# FM33LG0XX register map
File version: 1.0
CPU: SC123 r1p0, little endian, no MPU, no FPU, 3 interrupt priority bits
Registers are 32-bit, read-write, reset 0x0 unless marked. A register's access mark holds for its fields unless they carry their own. Offsets are from the block's base; [hi:lo] are bit positions; {n}, {i} and the like mark numbered series.

## CRC — CRC module information
Base 0x40010000
0x00 DR reset 0xFFFFFFFF — CRC Data Register
  [31:0] CRCDR — CRCDR field description
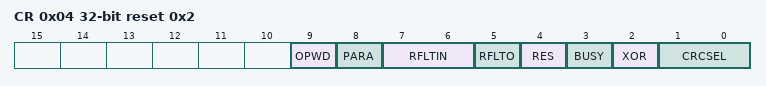
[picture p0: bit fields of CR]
0x04 CR access per field reset 0x2 — CRC Control Register
  [9] OPWD rw — OPWD field description
  [8] PARA rw — PARA field description
  [7:6] RFLTIN rw — RFLTIN field description
  [5] RFLTO rw — RFLTO field description
  [4] RES ro — RES field description
  [3] BUSY ro — BUSY field description
  [2] XOR rw — XOR field description
  [1:0] CRCSEL rw — CRCSEL field description
0x08 LFSR reset 0xFFFFFFFF — CRC Linear Feedback Shift Register
  [31:0] LFSR — LFSR field description
0x0C XOR — CRC output XOR Register
  [31:0] CRC_XOR — CRC_XOR field description
0x1C POLY reset 0x1021 — CRC Polynominal Register
  [31:0] CRCPOLY — CRCPOLY field description

## BSTIM32 — BSTIM32 module information
Base 0x40016000
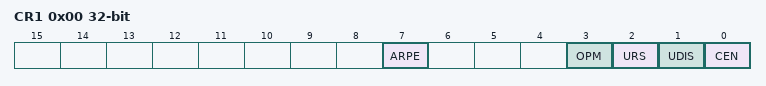
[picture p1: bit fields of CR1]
0x00 CR1 — BSTIM32 Control Register1
  [7] ARPE — ARPE field description
  [3] OPM — OPM field description
  [2] URS — URS field description
  [1] UDIS — UDIS field description
  [0] CEN — CEN field description
0x04 CR2 — BSTIM32 Control Register2
  [6:4] MMS — MMS field description
0x0C IER — BSTIM32 Interrupt Enable Register
  [0] UIE — UIE field description
0x10 ISR — BSTIM32 Interrupt Status Register
  [0] UIF — UIF field description
0x14 EGR wo — BSTIM32 Event Generation Register
  [0] UG — UG field description
0x24 CNT — BSTIM32 Counter Register
  [31:0] CNT — CNT field description
0x28 PSC — BSTIM32 Prescaler Register
  [31:0] PSC — PSC field description
0x2C ARR reset 0xFFFFFFFF — BSTIM32 Auto-Reload Register
  [31:0] ARR — ARR field description

## BSTIM — BSTIM module information
Base 0x40018C00
Registers as BSTIM32 (with BSTIM32 read as BSTIM); these are added or differ:
0x24 CNT — BSTIM Counter Register
  [15:0] CNT — CNT field description
0x28 PSC — BSTIM Prescaler Register
  [15:0] PSC — PSC field description
0x2C ARR reset 0xFFFF — BSTIM Auto-Reload Register
  [15:0] ARR — ARR field description

## LPTIM32 — LPTIM32 module information
Base 0x40013400
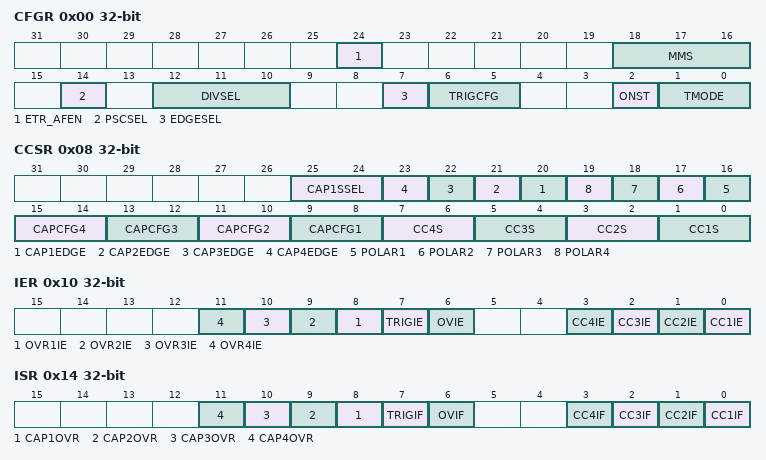
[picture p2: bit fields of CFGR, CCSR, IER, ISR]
0x00 CFGR — LPTIM32 Config Register
  [24] ETR_AFEN — ETR_AFEN field description
  [18:16] MMS — MMS field description
  [14] PSCSEL — PSCSEL field description
  [12:10] DIVSEL — DIVSEL field description
  [7] EDGESEL — EDGESEL field description
  [6:5] TRIGCFG — TRIGCFG field description
  [2] ONST — ONST field description
  [1:0] TMODE — TMODE field description
0x04 CNT ro — LPTIM32 Counter Register
  [31:0] CNT32 — CNT32 field description
0x08 CCSR access per field — LPTIM32 Capture/Compare Control and Status Register
  [25:24] CAP1SSEL rw — CAP1SSEL field description
  [n+19] CAP{n}EDGE ro (n=1..4) — CAP{n}EDGE field description
  [n+15] POLAR{n} rw (n=1..4) — POLAR{n} field description
  [2n+7:2n+6] CAPCFG{n} rw (n=1..4) — CAPCFG{n} field description
  [2n-1:2n-2] CC{n}S rw (n=1..4) — CC{n}S field description
0x0C ARR — LPTIM32 Auto-Reload Register
  [31:0] ARR — ARR field description
0x10 IER — LPTIM32 Interrupt Enable Register
  [n+7] OVR{n}IE (n=1..4) — OVR{n}IE field description
  [7] TRIGIE — TRIGIE field description
  [6] OVIE — OVIE field description
  [n-1] CC{n}IE (n=1..4) — CC{n}IE field description
0x14 ISR — LPTIM32 Interrupt Status Register
  [n+7] CAP{n}OVR (n=1..4) — CAP{n}OVR field description
  [7] TRIGIF — TRIGIF field description
  [6] OVIF — OVIF field description
  [n-1] CC{n}IF (n=1..4) — CC{n}IF field description
0x18 CR — LPTIM32 Control Register
  [0] EN — EN field description
{0x1C+4i} CCR{i} (i=1..4) — LPTIM32 Capture/Compare Register{i}
  [31:0] CCR{i} — CCR{i} field description

## LPTIM16 — LPTIM16 module information
Base 0x40018800
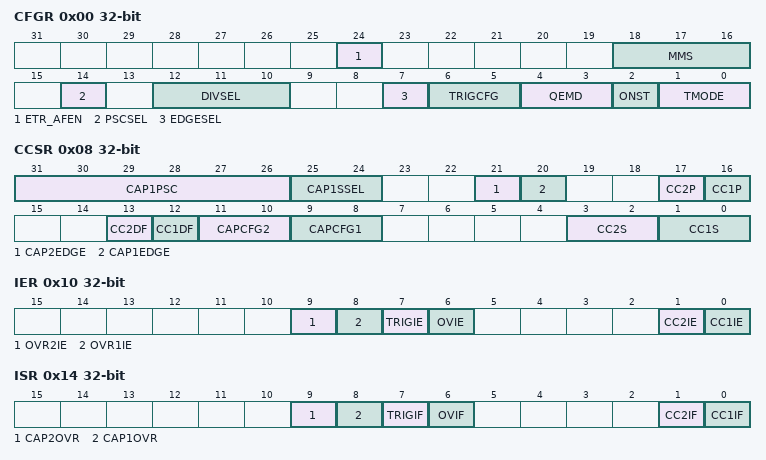
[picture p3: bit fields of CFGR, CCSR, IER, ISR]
0x00 CFGR — LPTIM16 Config Register
  [24] ETR_AFEN — ETR_AFEN field description
  [18:16] MMS — MMS field description
  [14] PSCSEL — PSCSEL field description
  [12:10] DIVSEL — DIVSEL field description
  [7] EDGESEL — EDGESEL field description
  [6:5] TRIGCFG — TRIGCFG field description
  [4:3] QEMD — QEMD field description
  [2] ONST — ONST field description
  [1:0] TMODE — TMODE field description
0x04 CNT ro — LPTIM16 Counter Register
  [15:0] CNT16 — CNT16 field description
0x08 CCSR access per field — LPTIM16 Capture/Compare Control and Status Register
  [31:26] CAP1PSC rw — CAP1PSC field description
  [25:24] CAP1SSEL rw — CAP1SSEL field description
  [21] CAP2EDGE ro — CAP2EDGE field description
  [20] CAP1EDGE ro — CAP1EDGE field description
  [17] CC2P rw — CC2P field description
  [16] CC1P rw — CC1P field description
  [13] CC2DF rw — CC2DF field description
  [12] CC1DF rw — CC1DF field description
  [11:10] CAPCFG2 rw — CAPCFG2 field description
  [9:8] CAPCFG1 rw — CAPCFG1 field description
  [3:2] CC2S rw — CC2S field description
  [1:0] CC1S rw — CC1S field description
0x0C ARR — LPTIM16 Auto-Reload Register
  [15:0] ARR — ARR field description
0x10 IER — LPTIM16 Interrupt Enable Register
  [9] OVR2IE — OVR2IE field description
  [8] OVR1IE — OVR1IE field description
  [7] TRIGIE — TRIGIE field description
  [6] OVIE — OVIE field description
  [1] CC2IE — CC2IE field description
  [0] CC1IE — CC1IE field description
0x14 ISR — LPTIM16 Interrupt Status Register
  [9] CAP2OVR — CAP2OVR field description
  [8] CAP1OVR — CAP1OVR field description
  [7] TRIGIF — TRIGIF field description
  [6] OVIF — OVIF field description
  [1] CC2IF — CC2IF field description
  [0] CC1IF — CC1IF field description
0x18 CR — LPTIM16 Control Register
  [0] EN — EN field description
0x20 CCR1 — LPTIM16 Capture/Compare Register1
  [15:0] CCR1 — CCR1 field description
0x24 CCR2 — LPTIM16 Capture/Compare Register2
  [15:0] CCR2 — CCR2 field description
